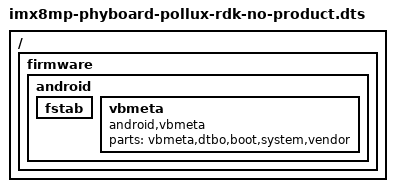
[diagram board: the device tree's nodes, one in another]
// SPDX-License-Identifier: GPL-2.0
/*
 * Copyright (C) 2021 PHYTEC Messtechnik GmbH
 * Author: Dominik Haller <d.haller@phytec.de>
 */

/dts-v1/;

#include "imx8mp-phyboard-pollux-rdk.dts"
/ {
	firmware {
		android {
			fstab {
				/delete-node/ product;
			};
			vbmeta {
				/*we need use FirstStageMountVBootV2 if we enable avb*/
				compatible = "android,vbmeta";
				/*parts means the partition witch can be mount in first stage*/
				parts = "vbmeta,dtbo,boot,system,vendor";
			};
		};
	};
};
